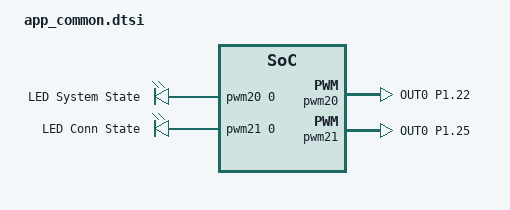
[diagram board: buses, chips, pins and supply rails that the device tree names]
/*
 * Copyright (c) 2025 Nordic Semiconductor ASA
 *
 * SPDX-License-Identifier: LicenseRef-Nordic-5-Clause
 */

/ {
	/* Disable pwmleds and redefine them to align configuration with CAF LEDs requirements. */
	/delete-node/ pwmleds;

	pwmleds0 {
		compatible = "pwm-leds";
		status = "okay";

		pwm_led0: led_pwm_0 {
			status = "okay";
			pwms = <&pwm20 0 PWM_MSEC(20) PWM_POLARITY_NORMAL>;
			label = "LED System State";
		};
	};

	pwmleds1 {
		compatible = "pwm-leds";
		status = "okay";

		pwm_led1: led_pwm_1 {
			status = "okay";
			pwms = <&pwm21 0 PWM_MSEC(20) PWM_POLARITY_NORMAL>;
			label = "LED Conn State";
		};
	};
};

&pwm20 {
	status = "okay";
	pinctrl-0 = <&pwm20_default_alt>;
	pinctrl-1 = <&pwm20_sleep_alt>;
	pinctrl-names = "default", "sleep";
};

&pwm21 {
	status = "okay";
	pinctrl-0 = <&pwm21_default_alt>;
	pinctrl-1 = <&pwm21_sleep_alt>;
	pinctrl-names = "default", "sleep";
};

&pinctrl {
	pwm20_default_alt: pwm20_default_alt {
		group1 {
			psels = <NRF_PSEL(PWM_OUT0, 1, 22)>;
		};
	};

	pwm20_sleep_alt: pwm20_sleep_alt {
		group1 {
			psels = <NRF_PSEL(PWM_OUT0, 1, 22)>;
			low-power-enable;
		};
	};

	pwm21_default_alt: pwm21_default_alt {
		group1 {
			psels = <NRF_PSEL(PWM_OUT0, 1, 25)>;
		};
	};

	pwm21_sleep_alt: pwm21_sleep_alt {
		group1 {
			psels = <NRF_PSEL(PWM_OUT0, 1, 25)>;
			low-power-enable;
		};
	};
};
